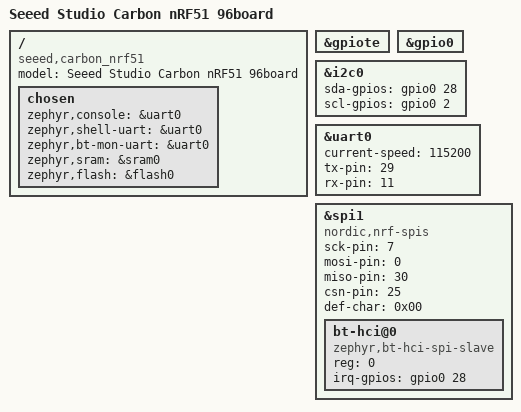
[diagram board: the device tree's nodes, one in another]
/*
 * Copyright (c) 2017 Linaro Limited
 *
 * SPDX-License-Identifier: Apache-2.0
 */

/dts-v1/;
#include <nordic/nrf51822_qfac.dtsi>

/ {
	model = "Seeed Studio Carbon nRF51 96board";
	compatible = "seeed,carbon_nrf51";

	chosen {
		zephyr,console = &uart0;
		zephyr,shell-uart = &uart0;
		zephyr,bt-mon-uart = &uart0;
		zephyr,sram = &sram0;
		zephyr,flash = &flash0;
	};
};

&gpiote {
	status = "okay";
};

&gpio0 {
	status = "okay";
};

&i2c0 {
	status = "okay";
	sda-gpios = <&gpio0 28 0>;
	scl-gpios = <&gpio0 2 0>;
};

&uart0 {
	current-speed = <115200>;
	status = "okay";
	tx-pin = <29>;
	rx-pin = <11>;
};

&spi1 {
	compatible = "nordic,nrf-spis";
	status = "okay";
	sck-pin = <7>;
	mosi-pin = <0>;
	miso-pin = <30>;
	csn-pin = <25>;
	def-char = <0x00>;

	bt-hci@0 {
		compatible = "zephyr,bt-hci-spi-slave";
		reg = <0>;
		irq-gpios = <&gpio0 28 (GPIO_ACTIVE_HIGH | GPIO_PULL_DOWN)>;
	};
};
